# WKUP_CTRL_MMR0_CFG0 register map
Vendor: Texas Instruments
Registers are 32-bit, read-write, reset 0x0 unless marked. A register's access mark holds for its fields unless they carry their own. Offsets are as the file gives them; [hi:lo] are bit positions; {n}, {i} and the like mark numbered series.

## WKUP_CTRL_MMR0_CFG0 (part 7 of 11)
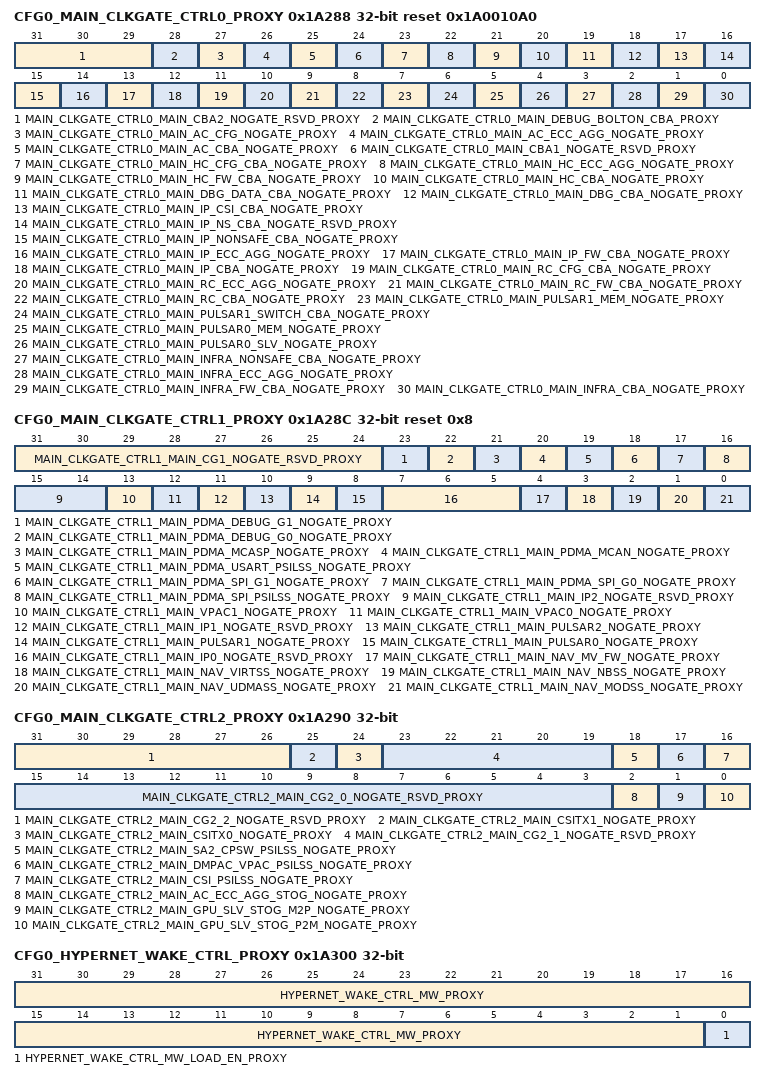
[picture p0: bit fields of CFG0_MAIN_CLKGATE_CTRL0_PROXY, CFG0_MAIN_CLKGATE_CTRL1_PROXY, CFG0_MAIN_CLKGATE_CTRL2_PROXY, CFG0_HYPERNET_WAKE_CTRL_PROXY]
0x1A288 CFG0_MAIN_CLKGATE_CTRL0_PROXY reset 0x1A0010A0 — Controls the power clock gating feature of MAIN domain modules and busses
  [31:29] MAIN_CLKGATE_CTRL0_MAIN_CBA2_NOGATE_RSVD_PROXY — MAIN CBA reserved clock gate disable. These bits should remain unchanged (written only with their default value) to maintain compatibility with future devices. 0 - Clocks are gated on idle for power savings 1 - Clocks are not gated on idle, power saving disabled
  [28] MAIN_CLKGATE_CTRL0_MAIN_DEBUG_BOLTON_CBA_PROXY — MAIN domain debug bolton bus (debug_bolton_cbass) clock gate disable. 0 - Clocks are gated on idle for power savings 1 - Clocks are not gated on idle, power saving disabled
  [27] MAIN_CLKGATE_CTRL0_MAIN_AC_CFG_NOGATE_PROXY — MAIN domain AC Configuration bus (ac_cfg_fw_cbass) clock gate disable. 0 - Clocks are gated on idle for power savings 1 - Clocks are not gated on idle, power saving disabled
  [26] MAIN_CLKGATE_CTRL0_MAIN_AC_ECC_AGG_NOGATE_PROXY — MAIN domain AC ECC aggregator bus (ac_pipe_ecc_aggr) clock gate disable. 0 - Clocks are gated on idle for power savings 1 - Clocks are not gated on idle, power saving disabled
  [25] MAIN_CLKGATE_CTRL0_MAIN_AC_CBA_NOGATE_PROXY — MAIN domain AC Firewall bus (ac_pipe_cbass_main_fw_cbass_0) clock gate disable. 0 - Clocks are gated on idle for power savings 1 - Clocks are not gated on idle, power saving disabled
  [24] MAIN_CLKGATE_CTRL0_MAIN_CBA1_NOGATE_RSVD_PROXY — MAIN CBA reserved clock gate disable. These bits should remain unchanged (written only with their default value) to maintain compatibility with future devices. 0 - Clocks are gated on idle for power savings 1 - Clocks are not gated on idle, power saving disabled
  [23] MAIN_CLKGATE_CTRL0_MAIN_HC_CFG_CBA_NOGATE_PROXY — MAIN domain HC Configuration bus (hc_cfg_cbass_0) clock gate disable. 0 - Clocks are gated on idle for power savings 1 - Clocks are not gated on idle, power saving disabled
  [22] MAIN_CLKGATE_CTRL0_MAIN_HC_ECC_AGG_NOGATE_PROXY — MAIN domain HC ECC aggregator (nogate) clock gate disable. 0 - Clocks are gated on idle for power savings 1 - Clocks are not gated on idle, power saving disabled
  [21] MAIN_CLKGATE_CTRL0_MAIN_HC_FW_CBA_NOGATE_PROXY — MAIN domain HC Firewall bus (main_hc2_fw_cbass_0) clock gate disable. 0 - Clocks are gated on idle for power savings 1 - Clocks are not gated on idle, power saving disabled
  [20] MAIN_CLKGATE_CTRL0_MAIN_HC_CBA_NOGATE_PROXY — MAIN domain HC Data bus (hc2_cbass_0) clock gate disable. 0 - Clocks are gated on idle for power savings 1 - Clocks are not gated on idle, power saving disabled
  [19] MAIN_CLKGATE_CTRL0_MAIN_DBG_DATA_CBA_NOGATE_PROXY — MAIN domain Debug Data bus (debug_cbass) clock gate disable. 0 - Clocks are gated on idle for power savings 1 - Clocks are not gated on idle, power saving disabled
  [18] MAIN_CLKGATE_CTRL0_MAIN_DBG_CBA_NOGATE_PROXY — MAIN domain Debug bus (debug_cbass_wrap_main_0) clock gate disable. 0 - Clocks are gated on idle for power savings 1 - Clocks are not gated on idle, power saving disabled
  [17] MAIN_CLKGATE_CTRL0_MAIN_IP_CSI_CBA_NOGATE_PROXY — MAIN domain CSI bus (csi_cbass_0) clock gate disable. 0 - Clocks are gated on idle for power savings 1 - Clocks are not gated on idle, power saving disabled
  [16] MAIN_CLKGATE_CTRL0_MAIN_IP_NS_CBA_NOGATE_RSVD_PROXY — MAIN nonsafety CBA reserved clock gate disable. These bits should remain unchanged (written only with their default value) to maintain compatibility with future devices. 0 - Clocks are gated on idle for power savings 1 - Clocks are not gated on idle, power saving disabled
  [15] MAIN_CLKGATE_CTRL0_MAIN_IP_NONSAFE_CBA_NOGATE_PROXY — MAIN domain Interface Peripheral nonsafety IP bus (ipphy_cbass_0) clock gate disable. 0 - Clocks are gated on idle for power savings 1 - Clocks are not gated on idle, power saving disabled
  [14] MAIN_CLKGATE_CTRL0_MAIN_IP_ECC_AGG_NOGATE_PROXY — MAIN domain Interface Peripheral ECC aggregator (main_spi0_g0_main_0_ecc_aggr_main_0) clock gate disable. 0 - Clocks are gated on idle for power savings 1 - Clocks are not gated on idle, power saving disabled
  [13] MAIN_CLKGATE_CTRL0_MAIN_IP_FW_CBA_NOGATE_PROXY — MAIN domain Interface Peripheral Firewall bus (ipphy_cbass_main_fw_cbass) clock gate disable. 0 - Clocks are gated on idle for power savings 1 - Clocks are not gated on idle, power saving disabled
  [12] MAIN_CLKGATE_CTRL0_MAIN_IP_CBA_NOGATE_PROXY — MAIN domain Interface Peripheral bus (ipphy_safe_cbass_0) clock gate disable. 0 - Clocks are gated on idle for power savings 1 - Clocks are not gated on idle, power saving disabled
  [11] MAIN_CLKGATE_CTRL0_MAIN_RC_CFG_CBA_NOGATE_PROXY — MAIN domain RC Configuration bus (rc_cfg_cbass_0) clock gate disable. 0 - Clocks are gated on idle for power savings 1 - Clocks are not gated on idle, power saving disabled
  [10] MAIN_CLKGATE_CTRL0_MAIN_RC_ECC_AGG_NOGATE_PROXY — MAIN domain RC ECC aggregator (main_rc_ecc_aggr_main_0) clock gate disable. 0 - Clocks are gated on idle for power savings 1 - Clocks are not gated on idle, power saving disabled
  [9] MAIN_CLKGATE_CTRL0_MAIN_RC_FW_CBA_NOGATE_PROXY — MAIN domain RC Firewall bus (rc_cbass_main_fw_cbass) clock gate disable. 0 - Clocks are gated on idle for power savings 1 - Clocks are not gated on idle, power saving disabled
  [8] MAIN_CLKGATE_CTRL0_MAIN_RC_CBA_NOGATE_PROXY — MAIN domain RC Data bus (rc_cbass_0) clock gate disable. 0 - Clocks are gated on idle for power savings 1 - Clocks are not gated on idle, power saving disabled
  [7] MAIN_CLKGATE_CTRL0_MAIN_PULSAR1_MEM_NOGATE_PROXY — MAIN domain Pulsar 1 memory bus (pulsar1_mem_cbass) clock gate disable. 0 - Clocks are gated on idle for power savings 1 - Clocks are not gated on idle, power saving disabled
  [6] MAIN_CLKGATE_CTRL0_MAIN_PULSAR1_SWITCH_CBA_NOGATE_PROXY — MAIN domain Pulsar 1 peripheral switch bus (pulsar1_periph_switch_cbass) clock gate disable. 0 - Clocks are gated on idle for power savings 1 - Clocks are not gated on idle, power saving disabled
  [5] MAIN_CLKGATE_CTRL0_MAIN_PULSAR0_MEM_NOGATE_PROXY — MAIN domain Pulsar 0 memory bus (pulsar0_mem_cbass) clock gate disable. 0 - Clocks are gated on idle for power savings 1 - Clocks are not gated on idle, power saving disabled
  [4] MAIN_CLKGATE_CTRL0_MAIN_PULSAR0_SLV_NOGATE_PROXY — MAIN domain Pulsar slave bus (pulsar0_slv_cbass) clock gate disable. 0 - Clocks are gated on idle for power savings 1 - Clocks are not gated on idle, power saving disabled
  [3] MAIN_CLKGATE_CTRL0_MAIN_INFRA_NONSAFE_CBA_NOGATE_PROXY — MAIN domain Infrastructure non-safety IP bus (main_infra_non_safe_cbass) clock gate disable. 0 - Clocks are gated on idle for power savings 1 - Clocks are not gated on idle, power saving disabled
  [2] MAIN_CLKGATE_CTRL0_MAIN_INFRA_ECC_AGG_NOGATE_PROXY — MAIN domain Infrastructure ECC aggregator (main_infra_ecc_aggr) clock gate disable. 0 - Clocks are gated on idle for power savings 1 - Clocks are not gated on idle, power saving disabled
  [1] MAIN_CLKGATE_CTRL0_MAIN_INFRA_FW_CBA_NOGATE_PROXY — MAIN domain Infrastructure Firewall bus (main_infra_fw_cbass) clock gate disable. 0 - Clocks are gated on idle for power savings 1 - Clocks are not gated on idle, power saving disabled
  [0] MAIN_CLKGATE_CTRL0_MAIN_INFRA_CBA_NOGATE_PROXY — MAIN domain Infrastructure bus (main_infra_cbass) clock gate disable. 0 - Clocks are gated on idle for power savings 1 - Clocks are not gated on idle, power saving disabled
0x1A28C CFG0_MAIN_CLKGATE_CTRL1_PROXY reset 0x8 — Controls the power clock gating feature of MAIN domain modules and busses
  [31:24] MAIN_CLKGATE_CTRL1_MAIN_CG1_NOGATE_RSVD_PROXY — MAIN PDMA clock gate disable. These bits should remain unchanged (written only with their default value) to maintain compatibility with future devices. 0 - Clocks are gated on idle for power savings 1 - Clocks are not gated on idle, power saving disabled
  [23] MAIN_CLKGATE_CTRL1_MAIN_PDMA_DEBUG_G1_NOGATE_PROXY — MAIN domain PDMA Debug_G1 clock gate disable. 0 - Clocks are gated on idle for power savings 1 - Clocks are not gated on idle, power saving disabled
  [22] MAIN_CLKGATE_CTRL1_MAIN_PDMA_DEBUG_G0_NOGATE_PROXY — MAIN domain PDMA Debug_G0 clock gate disable. 0 - Clocks are gated on idle for power savings 1 - Clocks are not gated on idle, power saving disabled
  [21] MAIN_CLKGATE_CTRL1_MAIN_PDMA_MCASP_NOGATE_PROXY — MAIN domain PDMA MCASP clock gate disable. 0 - Clocks are gated on idle for power savings 1 - Clocks are not gated on idle, power saving disabled
  [20] MAIN_CLKGATE_CTRL1_MAIN_PDMA_MCAN_NOGATE_PROXY — MAIN domain PDMA MCAN clock gate disable. 0 - Clocks are gated on idle for power savings 1 - Clocks are not gated on idle, power saving disabled
  [19] MAIN_CLKGATE_CTRL1_MAIN_PDMA_USART_PSILSS_NOGATE_PROXY — MAIN domain PDMA USART PSILSS clock gate disable. 0 - Clocks are gated on idle for power savings 1 - Clocks are not gated on idle, power saving disabled
  [18] MAIN_CLKGATE_CTRL1_MAIN_PDMA_SPI_G1_NOGATE_PROXY — MAIN domain PDMA SPI_G1 clock gate disable. 0 - Clocks are gated on idle for power savings 1 - Clocks are not gated on idle, power saving disabled
  [17] MAIN_CLKGATE_CTRL1_MAIN_PDMA_SPI_G0_NOGATE_PROXY — MAIN domain PDMA SPI_G0 clock gate disable. 0 - Clocks are gated on idle for power savings 1 - Clocks are not gated on idle, power saving disabled
  [16] MAIN_CLKGATE_CTRL1_MAIN_PDMA_SPI_PSILSS_NOGATE_PROXY — MAIN domain PDMA SPI PSILSS clock gate disable. 0 - Clocks are gated on idle for power savings 1 - Clocks are not gated on idle, power saving disabled
  [15:14] MAIN_CLKGATE_CTRL1_MAIN_IP2_NOGATE_RSVD_PROXY — MAIN IP reserved clock gate disable. These bits should remain unchanged (written only with their default value) to maintain compatibility with future devices. 0 - Clocks are gated on idle for power savings 1 - Clocks are not gated on idle, power saving disabled
  [13] MAIN_CLKGATE_CTRL1_MAIN_VPAC1_NOGATE_PROXY — MAIN domain VPAC 1 clock gate disable. 0 - Clocks are gated on idle for power savings 1 - Clocks are not gated on idle, power saving disabled
  [12] MAIN_CLKGATE_CTRL1_MAIN_VPAC0_NOGATE_PROXY — MAIN domain VPAC 0 clock gate disable. 0 - Clocks are gated on idle for power savings 1 - Clocks are not gated on idle, power saving disabled
  [11] MAIN_CLKGATE_CTRL1_MAIN_IP1_NOGATE_RSVD_PROXY — MAIN IP reserved clock gate disable. These bits should remain unchanged (written only with their default value) to maintain compatibility with future devices. 0 - Clocks are gated on idle for power savings 1 - Clocks are not gated on idle, power saving disabled
  [10] MAIN_CLKGATE_CTRL1_MAIN_PULSAR2_NOGATE_PROXY — MAIN domain Pulsar 2 clock gate disable. 0 - Clocks are gated on idle for power savings 1 - Clocks are not gated on idle, power saving disabled
  [9] MAIN_CLKGATE_CTRL1_MAIN_PULSAR1_NOGATE_PROXY — MAIN domain Pulsar 1 clock gate disable. 0 - Clocks are gated on idle for power savings 1 - Clocks are not gated on idle, power saving disabled
  [8] MAIN_CLKGATE_CTRL1_MAIN_PULSAR0_NOGATE_PROXY — MAIN domain Pulsar 0 clock gate disable. 0 - Clocks are gated on idle for power savings 1 - Clocks are not gated on idle, power saving disabled
  [7:5] MAIN_CLKGATE_CTRL1_MAIN_IP0_NOGATE_RSVD_PROXY — MAIN IP reserved clock gate disable. These bits should remain unchanged (written only with their default value) to maintain compatibility with future devices. 0 - Clocks are gated on idle for power savings 1 - Clocks are not gated on idle, power saving disabled
  [4] MAIN_CLKGATE_CTRL1_MAIN_NAV_MV_FW_NOGATE_PROXY — MAIN NavSS Mod/Virt Firewall interface clock gate disable. 0 - Clocks are gated on idle for power savings 1 - Clocks are not gated on idle, power saving disabled
  [3] MAIN_CLKGATE_CTRL1_MAIN_NAV_VIRTSS_NOGATE_PROXY — MAIN NavSS VIRTSS interface clock gate disable. 0 - Clocks are gated on idle for power savings 1 - Clocks are not gated on idle, power saving disabled
  [2] MAIN_CLKGATE_CTRL1_MAIN_NAV_NBSS_NOGATE_PROXY — MAIN NavSS NB interface clock gate disable. 0 - Clocks are gated on idle for power savings 1 - Clocks are not gated on idle, power saving disabled
  [1] MAIN_CLKGATE_CTRL1_MAIN_NAV_UDMASS_NOGATE_PROXY — Main NavSS UDMA interface clock gate disable. 0 - Clocks are gated on idle for power savings 1 - Clocks are not gated on idle, power saving disabled
  [0] MAIN_CLKGATE_CTRL1_MAIN_NAV_MODSS_NOGATE_PROXY — MAIN NavSS MODSS interface clock gate disable. 0 - Clocks are gated on idle for power savings 1 - Clocks are not gated on idle, power saving disabled
0x1A290 CFG0_MAIN_CLKGATE_CTRL2_PROXY — Controls the power clock gating feature of MAIN domain modules and busses
  [31:26] MAIN_CLKGATE_CTRL2_MAIN_CG2_2_NOGATE_RSVD_PROXY — MAIN domain spare clock gate disable. These bits should remain unchanged (written only with their default value) to maintain compatibility with future devices. 0 - Clocks are gated on idle for power savings 1 - Clocks are not gated on idle, power saving disabled
  [25] MAIN_CLKGATE_CTRL2_MAIN_CSITX1_NOGATE_PROXY — MAIN domain CSI_TX1 clock gate disable. 0 - Clocks are gated on idle for power savings 1 - Clocks are not gated on idle, power saving disabled
  [24] MAIN_CLKGATE_CTRL2_MAIN_CSITX0_NOGATE_PROXY — MAIN domain CSI_TX0 clock gate disable. 0 - Clocks are gated on idle for power savings 1 - Clocks are not gated on idle, power saving disabled
  [23:19] MAIN_CLKGATE_CTRL2_MAIN_CG2_1_NOGATE_RSVD_PROXY — MAIN domain spare clock gate disable. These bits should remain unchanged (written only with their default value) to maintain compatibility with future devices. 0 - Clocks are gated on idle for power savings 1 - Clocks are not gated on idle, power saving disabled
  [18] MAIN_CLKGATE_CTRL2_MAIN_SA2_CPSW_PSILSS_NOGATE_PROXY — MAIN domain SA2_UL/SPCW PSILSS clock gate disable. 0 - Clocks are gated on idle for power savings 1 - Clocks are not gated on idle, power saving disabled
  [17] MAIN_CLKGATE_CTRL2_MAIN_DMPAC_VPAC_PSILSS_NOGATE_PROXY — MAIN domain DMPAC/VPAC PSILSS clock gate disable. 0 - Clocks are gated on idle for power savings 1 - Clocks are not gated on idle, power saving disabled
  [16] MAIN_CLKGATE_CTRL2_MAIN_CSI_PSILSS_NOGATE_PROXY — MAIN domain CSI PSILSS clock gate disable. 0 - Clocks are gated on idle for power savings 1 - Clocks are not gated on idle, power saving disabled
  [15:3] MAIN_CLKGATE_CTRL2_MAIN_CG2_0_NOGATE_RSVD_PROXY — MAIN domain spare clock gate disable. These bits should remain unchanged (written only with their default value) to maintain compatibility with future devices. 0 - Clocks are gated on idle for power savings 1 - Clocks are not gated on idle, power saving disabled
  [2] MAIN_CLKGATE_CTRL2_MAIN_AC_ECC_AGG_STOG_NOGATE_PROXY — MAIN domain ac ECC aggregator Slave Timeout Gasket (main_ac_ecc_aggr_stog) clock gate disable. 0 - Clocks are gated on idle for power savings 1 - Clocks are not gated on idle, power saving disabled
  [1] MAIN_CLKGATE_CTRL2_MAIN_GPU_SLV_STOG_M2P_NOGATE_PROXY — MAIN domain GPU Slave Timeout Gasket output (main_gpu_slv_stog_m2p_pwr_dis) clock gate disable. 0 - Clocks are gated on idle for power savings 1 - Clocks are not gated on idle, power saving disabled
  [0] MAIN_CLKGATE_CTRL2_MAIN_GPU_SLV_STOG_P2M_NOGATE_PROXY — MAIN domain GPU Slave Timeout Gasket input (main_gpu_slv_stog_p2m_pwr_dis) clock gate disable. 0 - Clocks are gated on idle for power savings 1 - Clocks are not gated on idle, power saving disabled
0x1A294 CFG0_MAIN_CLKGATE_CTRL3_PROXY — Controls the power clock gating feature of MAIN domain modules and busses
  [31:0] MAIN_CLKGATE_CTRL3_MAIN_CG3_NOGATE_RSVD_PROXY — MAIN domain spare clock gate disable. These bits should remain unchanged (written only with their default value) to maintain compatibility with future devices. 0 - Clocks are gated on idle for power savings 1 - Clocks are not gated on idle, power saving disabled
0x1A300 CFG0_HYPERNET_WAKE_CTRL_PROXY — Controls the operation of IO wakeup on the MAIN HYPERNET pins
  [31:1] HYPERNET_WAKE_CTRL_MW_PROXY — HYPERNET IO magic word. This 31-bit value that enables placing of the HYPERNET I/Os into isolation for daisy-chain wakeup operation. 0x2AAAAAAA - Magic word value to enable isolation when qualified with mw_load bit Others - Any other value will prevent isolation when mw_load transitions from 0 to 1.
  [0] HYPERNET_WAKE_CTRL_MW_LOAD_EN_PROXY — Magic word load enableSetting this bit to 1 loads and locks the mw field for HYPERNET IO isolation. If the mw field matches the magic word value then the value is latched into the HYPERNET IO voltage domain and HYPERNET IO isolation is enabled. 0 - Unlock and do not load mw value for comparison 1 - Load and lock mw for magic word value comparison
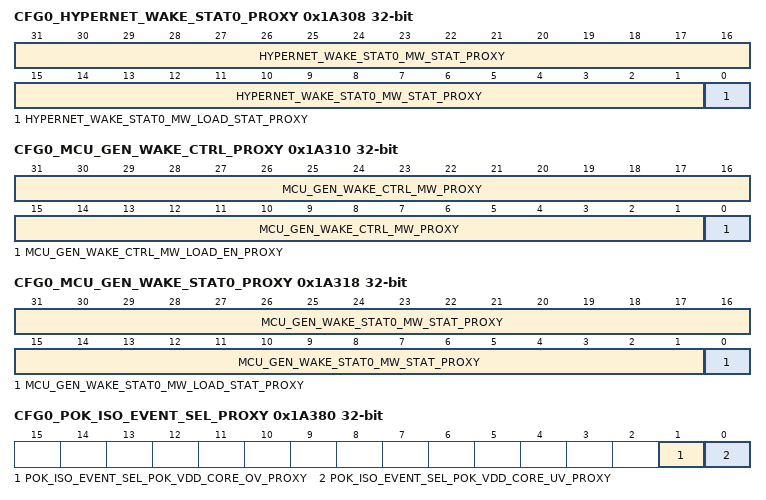
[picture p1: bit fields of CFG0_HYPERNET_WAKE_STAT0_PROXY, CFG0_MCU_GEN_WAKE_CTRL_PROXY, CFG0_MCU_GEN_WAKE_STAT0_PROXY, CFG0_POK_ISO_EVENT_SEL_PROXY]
0x1A308 CFG0_HYPERNET_WAKE_STAT0_PROXY ro — Provides the status of MAIN HYPERNET_WAKE control bits
  [31:1] HYPERNET_WAKE_STAT0_MW_STAT_PROXY — HYPERNET magic word statusIndicates the latched value of the mw field.
  [0] HYPERNET_WAKE_STAT0_MW_LOAD_STAT_PROXY — Magic word load status.Indicates the latched value of the mw_load_en bit
0x1A30C CFG0_HYPERNET_WAKE_STAT1_PROXY ro — Provides MAIN HYPERNET IO isolation status
  [0] HYPERNET_WAKE_STAT1_HYPERNET_IO_MODE_PROXY — Indicates if HYPERNET IO wakeup mode is enabled. 0 - Not enabled (load_en not set or mw doesn't match magic word) 1 - HYPERNET IO mode enabled
0x1A310 CFG0_MCU_GEN_WAKE_CTRL_PROXY — Controls the operation of IO wakeup on the MCU_GENERAL pins
  [31:1] MCU_GEN_WAKE_CTRL_MW_PROXY — MCU_GENERAL IO magic word. This 31-bit value that enables placing of the MCU_GENERAL I/Os into isolation for daisy-chain wakeup operation. 0x2AAAAAAA - Magic word value to enable isolation when qualified with mw_load bit Others - Any other value will prevent isolation when mw_load transitions from 0 to 1.
  [0] MCU_GEN_WAKE_CTRL_MW_LOAD_EN_PROXY — Magic word load enableSetting this bit to 1 loads and locks the mw field for MCU_GENERAL IO isolation. If the mw field matches the magic word value then the value is latched into the MCU_GENERAL IO voltage domain and MCU_GENERAL IO isolation is enabled. 0 - Unlock and do not load mw value for comparison 1 - Load and lock mw for magic word value comparison
0x1A318 CFG0_MCU_GEN_WAKE_STAT0_PROXY ro — Provides the status of MCU_GEN_WAKE control bits
  [31:1] MCU_GEN_WAKE_STAT0_MW_STAT_PROXY — MCU_GENERAL magic word statusIndicates the latched value of the mw field.
  [0] MCU_GEN_WAKE_STAT0_MW_LOAD_STAT_PROXY — Magic word load status.Indicates the latched value of the mw_load_en bit
0x1A31C CFG0_MCU_GEN_WAKE_STAT1_PROXY ro — Provides MCU_GENERAL IO isolation status
  [0] MCU_GEN_WAKE_STAT1_MCU_GEN_IO_MODE_PROXY — Indicates if MCU_GENERAL IO wakeup mode is enabled. 0 - Not enabled (load_en not set or mw doesn't match magic word) 1 - MCU_GENERAL IO mode enabled
0x1A380 CFG0_POK_ISO_EVENT_SEL_PROXY — Determines which POK events activate isolation features
  [1] POK_ISO_EVENT_SEL_POK_VDD_CORE_OV_PROXY — VDD_CORE overvoltage detection triggers enabled isolation actions
  [0] POK_ISO_EVENT_SEL_POK_VDD_CORE_UV_PROXY — VDD_CORE undervoltage detection triggers enabled isolation actions
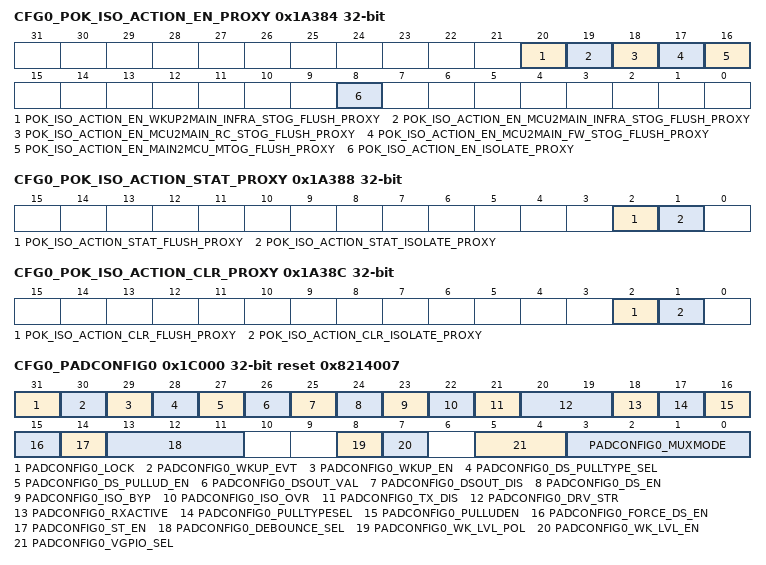
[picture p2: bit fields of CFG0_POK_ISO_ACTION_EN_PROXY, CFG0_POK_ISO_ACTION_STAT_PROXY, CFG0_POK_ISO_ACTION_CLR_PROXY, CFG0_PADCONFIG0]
0x1A384 CFG0_POK_ISO_ACTION_EN_PROXY — Selects which isolation actions to perform when POK events as selected in POK_ISO_EVENT_SEL occur
  [20] POK_ISO_ACTION_EN_WKUP2MAIN_INFRA_STOG_FLUSH_PROXY — WKUP to Main INFRA slave timeout gasket flush enable: 0 - Enabled POK events have no effect on this gasket 1 - Enabled POK events will assert the flush for this gasket
  [19] POK_ISO_ACTION_EN_MCU2MAIN_INFRA_STOG_FLUSH_PROXY — MCU to Main INFRA slave timeout gasket flush enable: 0 - Enabled POK events have no effect on this gasket 1 - Enabled POK events will assert the flush for this gasket
  [18] POK_ISO_ACTION_EN_MCU2MAIN_RC_STOG_FLUSH_PROXY — MCU to Main RC slave timeout gasket flush enable: 0 - Enabled POK events have no effect on this gasket 1 - Enabled POK events will assert the flush for this gasket
  [17] POK_ISO_ACTION_EN_MCU2MAIN_FW_STOG_FLUSH_PROXY — MCU to Main FW slave timeout gasket flush enable: 0 - Enabled POK events have no effect on this gasket 1 - Enabled POK events will assert the flush for this gasket
  [16] POK_ISO_ACTION_EN_MAIN2MCU_MTOG_FLUSH_PROXY — MAIN to MCU master timeout gasket flush enable: 0 - Enabled POK events have no effect on this gasket 1 - Enabled POK events will assert the flush for this gasket
  [8] POK_ISO_ACTION_EN_ISOLATE_PROXY — If enabled, the isolate signal will be asserted after all enabled flush signals have been asserted for 4 of their respective time-out gasket clocks when any selected POK event occurs. 0 - Isolation is not asserted on selected POK event 1 - Isolation signal is asserted on selected POK event after enabled TOG flush
0x1A388 CFG0_POK_ISO_ACTION_STAT_PROXY ro — Indicates the status of enabled POK isolation actions
  [2] POK_ISO_ACTION_STAT_FLUSH_PROXY — POK activated timeout gasket flush statusThis signal will remain asserted until a 1 is written to the POK_ISO_ACTION_CLR_flush bit. 0 - No gasket flush is being asserted by enabled POK event 1 - Enabled gasket flush signals are being asserted due to an enabled POK event
  [1] POK_ISO_ACTION_STAT_ISOLATE_PROXY — POK activated Isolate statusThis signal will remain asserted until a 1 is written to the POK_ISO_ACTION_CLR_isolate bit. 0 - No isolate is being asserted by enabled POK event 1 - Isolate signal is being asserted due to an enabled POK event
0x1A38C CFG0_POK_ISO_ACTION_CLR_PROXY — Selects which active POK isolation actions to clear
  [2] POK_ISO_ACTION_CLR_FLUSH_PROXY — POK activated timeout gasket flush clearAlways read as 0. Writing 1 deasserts POK activated timeot gasket flush signals. 0 - Writing 0 has no effect. Bit always reads as 0 1 - Deassert gasket flush signals. Bit will clear to 0 after write.
  [1] POK_ISO_ACTION_CLR_ISOLATE_PROXY — POK activated isolate clearAlways read as 0. Writing 1 deasserts POK activated isolate signal. 0 - Writing 0 has no effect. Bit always reads as 0 1 - Deassert isolate signal. Bit will clear to 0 after write.
{0x1B100+4i} CFG0_CLAIMREG_P6_R{i} (i=0..7)
  [31:0] CLAIMREG_P6_R{i} — Claim bits for Partition 6
0x1C000 CFG0_PADCONFIG0 access per field reset 0x8214007 — Register to control pin configuration and muxing
  [31] PADCONFIG0_LOCK rw — Lock 0 - Padconfig register is unlocked 1 - Padconfig register is locked from further writes
  [30] PADCONFIG0_WKUP_EVT ro — Wakeup event status 0 - No wake event on pin 1 - Wake event occurred on pin
  [29] PADCONFIG0_WKUP_EN rw — Wakeup enable 0 - Wakeup operation disabled 1 - Wakeup operation enabled
  [28] PADCONFIG0_DS_PULLTYPE_SEL rw — Deep Sleep pull-up/down selection 0 - Offmode pulldown selected 1 - Offmode pullup selected
  [27] PADCONFIG0_DS_PULLUD_EN rw — Deep Sleep pull-up/down enable (active low) 0 - Pullup / pulldown is enabled 1 - Pullup / pulldown is disabled
  [26] PADCONFIG0_DSOUT_VAL rw — Deep Sleep output value 0 - Output value is 0 1 - Output value is 1
  [25] PADCONFIG0_DSOUT_DIS rw — Deep Sleep output enable 0 - Output enabled 1 - Output disabled
  [24] PADCONFIG0_DS_EN rw — Deep Sleep override control 0 - IO keeps its previous state when Deep Sleep is active 1 - IO state is forced to OFF mode value when Deep Sleep is active
  [23] PADCONFIG0_ISO_BYP rw — Isolation Bypass0 - IO isolation is preserved1 - IO isolation is bypassed
  [22] PADCONFIG0_ISO_OVR rw — Isolation Override0 - IO isolation is preserved1 - IO isolation is overridden
  [21] PADCONFIG0_TX_DIS rw — Driver Disable0 - Driver is enabled1 - Driver is disabled
  [20:19] PADCONFIG0_DRV_STR rw — Drive Strength Control . Selects the drive strength value for LVCMOS pins. (Does not apply to other pin types)
  [18] PADCONFIG0_RXACTIVE rw — Input enable for the Pad0 - Receiver disabled1 - Receiver enabled
  [17] PADCONFIG0_PULLTYPESEL rw — Pad Pullup / Pulldown type selection0 - Pulldown selected1 - Pullup selected
  [16] PADCONFIG0_PULLUDEN rw — Pad Pullup / Pulldown enable. This is an active low signal.0 - Pullup / Pulldown enabled1 - Pullup / Pulldown disabled
  [15] PADCONFIG0_FORCE_DS_EN rw — Enable pad Deep Sleep controls by overriding SMS gating0 - Deep Sleep pad controls are gated by the SMS1 - Activate Deep Sleep pad controls (override SMS gating logic)
  [14] PADCONFIG0_ST_EN rw — Receiver Schmitt Trigger enable 0 - Schmitt trigger input disabled 1 - Schmitt trigger input enabled
  [13:11] PADCONFIG0_DEBOUNCE_SEL rw — Selects the debounce period for the pad.
  [8] PADCONFIG0_WK_LVL_POL rw — Level Sensitive Wakeup PolarityThis bit is not relevant unless wk_lvl_en is set to 1'b1.0 - Low. A low (0) value on the pin causes a wakeup1 - High. A high (1) value on the pin causes a wakeup
  [7] PADCONFIG0_WK_LVL_EN rw — Level Sensitive Wakeup Enable0 - Disabled. Wakeup is triggered by change of the pin input value1 - Enabled. Wakeup is triggered when the pin matches the value specified by wk_lvl_pol. The chosen polarity must be maintained. (e.g. until wakeup completion is confirmed)
  [5:4] PADCONFIG0_VGPIO_SEL rw — Virtual WKUP_GPIO instance select.These bits select which instance of GPIO is used for this I/O pad. This allows protection between two different Processor virtual worlds. These bits have no effect if GPIO mode (muxmode=7) is not selected for the PAD. Field values (Others are reserved): 2'b00 - Implement GPIO in GPIO_WKUP_0 instance 2'b01 - Implement GPIO in GPIO_WKUP_1 instance
  [3:0] PADCONFIG0_MUXMODE rw — Pad functional signal mux selection Field values (Others are reserved): 0000b - Mux Mode 0 0001b - Mux Mode 1 0010b - Mux Mode 2 0011b - Mux Mode 3 0100b - Mux Mode 4 0101b - Mux Mode 5 0110b - Mux Mode 6 0111b - Mux Mode 7 1111b - Mux Mode 15
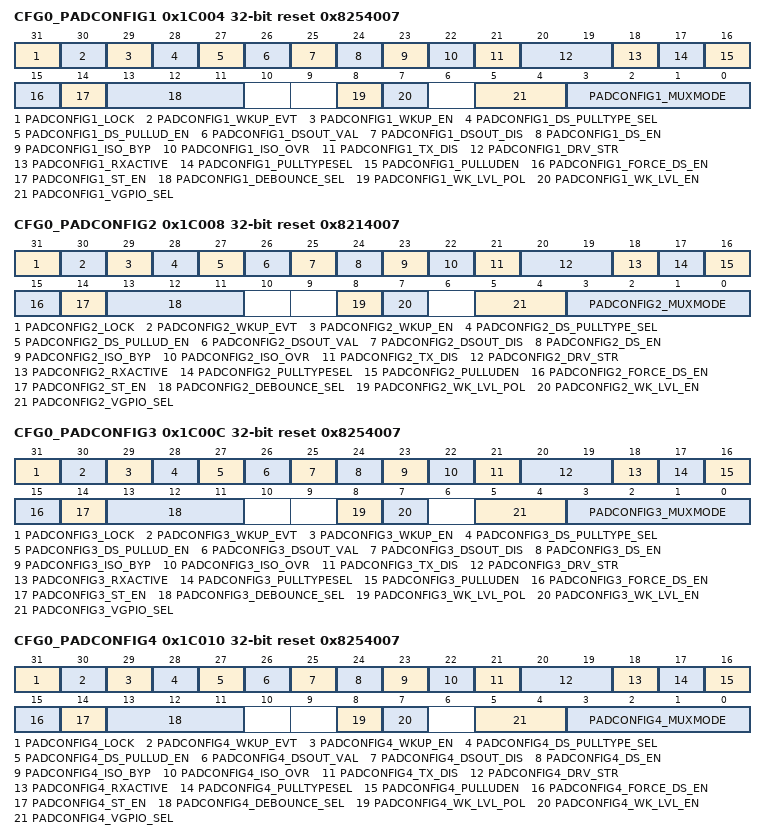
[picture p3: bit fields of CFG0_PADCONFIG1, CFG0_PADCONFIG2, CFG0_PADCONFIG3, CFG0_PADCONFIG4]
0x1C004 CFG0_PADCONFIG1 access per field reset 0x8254007 — Register to control pin configuration and muxing
  [31] PADCONFIG1_LOCK rw — Lock 0 - Padconfig register is unlocked 1 - Padconfig register is locked from further writes
  [30] PADCONFIG1_WKUP_EVT ro — Wakeup event status 0 - No wake event on pin 1 - Wake event occurred on pin
  [29] PADCONFIG1_WKUP_EN rw — Wakeup enable 0 - Wakeup operation disabled 1 - Wakeup operation enabled
  [28] PADCONFIG1_DS_PULLTYPE_SEL rw — Deep Sleep pull-up/down selection 0 - Offmode pulldown selected 1 - Offmode pullup selected
  [27] PADCONFIG1_DS_PULLUD_EN rw — Deep Sleep pull-up/down enable (active low) 0 - Pullup / pulldown is enabled 1 - Pullup / pulldown is disabled
  [26] PADCONFIG1_DSOUT_VAL rw — Deep Sleep output value 0 - Output value is 0 1 - Output value is 1
  [25] PADCONFIG1_DSOUT_DIS rw — Deep Sleep output enable 0 - Output enabled 1 - Output disabled
  [24] PADCONFIG1_DS_EN rw — Deep Sleep override control 0 - IO keeps its previous state when Deep Sleep is active 1 - IO state is forced to OFF mode value when Deep Sleep is active
  [23] PADCONFIG1_ISO_BYP rw — Isolation Bypass0 - IO isolation is preserved1 - IO isolation is bypassed
  [22] PADCONFIG1_ISO_OVR rw — Isolation Override0 - IO isolation is preserved1 - IO isolation is overridden
  [21] PADCONFIG1_TX_DIS rw — Driver Disable0 - Driver is enabled1 - Driver is disabled
  [20:19] PADCONFIG1_DRV_STR rw — Drive Strength Control . Selects the drive strength value for LVCMOS pins. (Does not apply to other pin types)
  [18] PADCONFIG1_RXACTIVE rw — Input enable for the Pad0 - Receiver disabled1 - Receiver enabled
  [17] PADCONFIG1_PULLTYPESEL rw — Pad Pullup / Pulldown type selection0 - Pulldown selected1 - Pullup selected
  [16] PADCONFIG1_PULLUDEN rw — Pad Pullup / Pulldown enable. This is an active low signal.0 - Pullup / Pulldown enabled1 - Pullup / Pulldown disabled
  [15] PADCONFIG1_FORCE_DS_EN rw — Enable pad Deep Sleep controls by overriding SMS gating0 - Deep Sleep pad controls are gated by the SMS1 - Activate Deep Sleep pad controls (override SMS gating logic)
  [14] PADCONFIG1_ST_EN rw — Receiver Schmitt Trigger enable 0 - Schmitt trigger input disabled 1 - Schmitt trigger input enabled
  [13:11] PADCONFIG1_DEBOUNCE_SEL rw — Selects the debounce period for the pad.
  [8] PADCONFIG1_WK_LVL_POL rw — Level Sensitive Wakeup PolarityThis bit is not relevant unless wk_lvl_en is set to 1'b1.0 - Low. A low (0) value on the pin causes a wakeup1 - High. A high (1) value on the pin causes a wakeup
  [7] PADCONFIG1_WK_LVL_EN rw — Level Sensitive Wakeup Enable0 - Disabled. Wakeup is triggered by change of the pin input value1 - Enabled. Wakeup is triggered when the pin matches the value specified by wk_lvl_pol. The chosen polarity must be maintained. (e.g. until wakeup completion is confirmed)
  [5:4] PADCONFIG1_VGPIO_SEL rw — Virtual WKUP_GPIO instance select.These bits select which instance of GPIO is used for this I/O pad. This allows protection between two different Processor virtual worlds. These bits have no effect if GPIO mode (muxmode=7) is not selected for the PAD. Field values (Others are reserved): 2'b00 - Implement GPIO in GPIO_WKUP_0 instance 2'b01 - Implement GPIO in GPIO_WKUP_1 instance
  [3:0] PADCONFIG1_MUXMODE rw — Pad functional signal mux selection Field values (Others are reserved): 0000b - Mux Mode 0 0001b - Mux Mode 1 0010b - Mux Mode 2 0011b - Mux Mode 3 0100b - Mux Mode 4 0101b - Mux Mode 5 0110b - Mux Mode 6 0111b - Mux Mode 7 1111b - Mux Mode 15
0x1C008 CFG0_PADCONFIG2 access per field reset 0x8214007 — Register to control pin configuration and muxing
  [31] PADCONFIG2_LOCK rw — Lock 0 - Padconfig register is unlocked 1 - Padconfig register is locked from further writes
  [30] PADCONFIG2_WKUP_EVT ro — Wakeup event status 0 - No wake event on pin 1 - Wake event occurred on pin
  [29] PADCONFIG2_WKUP_EN rw — Wakeup enable 0 - Wakeup operation disabled 1 - Wakeup operation enabled
  [28] PADCONFIG2_DS_PULLTYPE_SEL rw — Deep Sleep pull-up/down selection 0 - Offmode pulldown selected 1 - Offmode pullup selected
  [27] PADCONFIG2_DS_PULLUD_EN rw — Deep Sleep pull-up/down enable (active low) 0 - Pullup / pulldown is enabled 1 - Pullup / pulldown is disabled
  [26] PADCONFIG2_DSOUT_VAL rw — Deep Sleep output value 0 - Output value is 0 1 - Output value is 1
  [25] PADCONFIG2_DSOUT_DIS rw — Deep Sleep output enable 0 - Output enabled 1 - Output disabled
  [24] PADCONFIG2_DS_EN rw — Deep Sleep override control 0 - IO keeps its previous state when Deep Sleep is active 1 - IO state is forced to OFF mode value when Deep Sleep is active
  [23] PADCONFIG2_ISO_BYP rw — Isolation Bypass0 - IO isolation is preserved1 - IO isolation is bypassed
  [22] PADCONFIG2_ISO_OVR rw — Isolation Override0 - IO isolation is preserved1 - IO isolation is overridden
  [21] PADCONFIG2_TX_DIS rw — Driver Disable0 - Driver is enabled1 - Driver is disabled
  [20:19] PADCONFIG2_DRV_STR rw — Drive Strength Control . Selects the drive strength value for LVCMOS pins. (Does not apply to other pin types)
  [18] PADCONFIG2_RXACTIVE rw — Input enable for the Pad0 - Receiver disabled1 - Receiver enabled
  [17] PADCONFIG2_PULLTYPESEL rw — Pad Pullup / Pulldown type selection0 - Pulldown selected1 - Pullup selected
  [16] PADCONFIG2_PULLUDEN rw — Pad Pullup / Pulldown enable. This is an active low signal.0 - Pullup / Pulldown enabled1 - Pullup / Pulldown disabled
  [15] PADCONFIG2_FORCE_DS_EN rw — Enable pad Deep Sleep controls by overriding SMS gating0 - Deep Sleep pad controls are gated by the SMS1 - Activate Deep Sleep pad controls (override SMS gating logic)
  [14] PADCONFIG2_ST_EN rw — Receiver Schmitt Trigger enable 0 - Schmitt trigger input disabled 1 - Schmitt trigger input enabled
  [13:11] PADCONFIG2_DEBOUNCE_SEL rw — Selects the debounce period for the pad.
  [8] PADCONFIG2_WK_LVL_POL rw — Level Sensitive Wakeup PolarityThis bit is not relevant unless wk_lvl_en is set to 1'b1.0 - Low. A low (0) value on the pin causes a wakeup1 - High. A high (1) value on the pin causes a wakeup
  [7] PADCONFIG2_WK_LVL_EN rw — Level Sensitive Wakeup Enable0 - Disabled. Wakeup is triggered by change of the pin input value1 - Enabled. Wakeup is triggered when the pin matches the value specified by wk_lvl_pol. The chosen polarity must be maintained. (e.g. until wakeup completion is confirmed)
  [5:4] PADCONFIG2_VGPIO_SEL rw — Virtual WKUP_GPIO instance select.These bits select which instance of GPIO is used for this I/O pad. This allows protection between two different Processor virtual worlds. These bits have no effect if GPIO mode (muxmode=7) is not selected for the PAD. Field values (Others are reserved): 2'b00 - Implement GPIO in GPIO_WKUP_0 instance 2'b01 - Implement GPIO in GPIO_WKUP_1 instance
  [3:0] PADCONFIG2_MUXMODE rw — Pad functional signal mux selection Field values (Others are reserved): 0000b - Mux Mode 0 0001b - Mux Mode 1 0010b - Mux Mode 2 0011b - Mux Mode 3 0100b - Mux Mode 4 0101b - Mux Mode 5 0110b - Mux Mode 6 0111b - Mux Mode 7 1111b - Mux Mode 15
0x1C00C CFG0_PADCONFIG3 access per field reset 0x8254007 — Register to control pin configuration and muxing
  [31] PADCONFIG3_LOCK rw — Lock 0 - Padconfig register is unlocked 1 - Padconfig register is locked from further writes
  [30] PADCONFIG3_WKUP_EVT ro — Wakeup event status 0 - No wake event on pin 1 - Wake event occurred on pin
  [29] PADCONFIG3_WKUP_EN rw — Wakeup enable 0 - Wakeup operation disabled 1 - Wakeup operation enabled
  [28] PADCONFIG3_DS_PULLTYPE_SEL rw — Deep Sleep pull-up/down selection 0 - Offmode pulldown selected 1 - Offmode pullup selected
  [27] PADCONFIG3_DS_PULLUD_EN rw — Deep Sleep pull-up/down enable (active low) 0 - Pullup / pulldown is enabled 1 - Pullup / pulldown is disabled
  [26] PADCONFIG3_DSOUT_VAL rw — Deep Sleep output value 0 - Output value is 0 1 - Output value is 1
  [25] PADCONFIG3_DSOUT_DIS rw — Deep Sleep output enable 0 - Output enabled 1 - Output disabled
  [24] PADCONFIG3_DS_EN rw — Deep Sleep override control 0 - IO keeps its previous state when Deep Sleep is active 1 - IO state is forced to OFF mode value when Deep Sleep is active
  [23] PADCONFIG3_ISO_BYP rw — Isolation Bypass0 - IO isolation is preserved1 - IO isolation is bypassed
  [22] PADCONFIG3_ISO_OVR rw — Isolation Override0 - IO isolation is preserved1 - IO isolation is overridden
  [21] PADCONFIG3_TX_DIS rw — Driver Disable0 - Driver is enabled1 - Driver is disabled
  [20:19] PADCONFIG3_DRV_STR rw — Drive Strength Control . Selects the drive strength value for LVCMOS pins. (Does not apply to other pin types)
  [18] PADCONFIG3_RXACTIVE rw — Input enable for the Pad0 - Receiver disabled1 - Receiver enabled
  [17] PADCONFIG3_PULLTYPESEL rw — Pad Pullup / Pulldown type selection0 - Pulldown selected1 - Pullup selected
  [16] PADCONFIG3_PULLUDEN rw — Pad Pullup / Pulldown enable. This is an active low signal.0 - Pullup / Pulldown enabled1 - Pullup / Pulldown disabled
  [15] PADCONFIG3_FORCE_DS_EN rw — Enable pad Deep Sleep controls by overriding SMS gating0 - Deep Sleep pad controls are gated by the SMS1 - Activate Deep Sleep pad controls (override SMS gating logic)
  [14] PADCONFIG3_ST_EN rw — Receiver Schmitt Trigger enable 0 - Schmitt trigger input disabled 1 - Schmitt trigger input enabled
  [13:11] PADCONFIG3_DEBOUNCE_SEL rw — Selects the debounce period for the pad.
  [8] PADCONFIG3_WK_LVL_POL rw — Level Sensitive Wakeup PolarityThis bit is not relevant unless wk_lvl_en is set to 1'b1.0 - Low. A low (0) value on the pin causes a wakeup1 - High. A high (1) value on the pin causes a wakeup
  [7] PADCONFIG3_WK_LVL_EN rw — Level Sensitive Wakeup Enable0 - Disabled. Wakeup is triggered by change of the pin input value1 - Enabled. Wakeup is triggered when the pin matches the value specified by wk_lvl_pol. The chosen polarity must be maintained. (e.g. until wakeup completion is confirmed)
  [5:4] PADCONFIG3_VGPIO_SEL rw — Virtual WKUP_GPIO instance select.These bits select which instance of GPIO is used for this I/O pad. This allows protection between two different Processor virtual worlds. These bits have no effect if GPIO mode (muxmode=7) is not selected for the PAD. Field values (Others are reserved): 2'b00 - Implement GPIO in GPIO_WKUP_0 instance 2'b01 - Implement GPIO in GPIO_WKUP_1 instance
  [3:0] PADCONFIG3_MUXMODE rw — Pad functional signal mux selection Field values (Others are reserved): 0000b - Mux Mode 0 0001b - Mux Mode 1 0010b - Mux Mode 2 0011b - Mux Mode 3 0100b - Mux Mode 4 0101b - Mux Mode 5 0110b - Mux Mode 6 0111b - Mux Mode 7 1111b - Mux Mode 15
0x1C010 CFG0_PADCONFIG4 access per field reset 0x8254007 — Register to control pin configuration and muxing
  [31] PADCONFIG4_LOCK rw — Lock 0 - Padconfig register is unlocked 1 - Padconfig register is locked from further writes
  [30] PADCONFIG4_WKUP_EVT ro — Wakeup event status 0 - No wake event on pin 1 - Wake event occurred on pin
  [29] PADCONFIG4_WKUP_EN rw — Wakeup enable 0 - Wakeup operation disabled 1 - Wakeup operation enabled
  [28] PADCONFIG4_DS_PULLTYPE_SEL rw — Deep Sleep pull-up/down selection 0 - Offmode pulldown selected 1 - Offmode pullup selected
  [27] PADCONFIG4_DS_PULLUD_EN rw — Deep Sleep pull-up/down enable (active low) 0 - Pullup / pulldown is enabled 1 - Pullup / pulldown is disabled
  [26] PADCONFIG4_DSOUT_VAL rw — Deep Sleep output value 0 - Output value is 0 1 - Output value is 1
  [25] PADCONFIG4_DSOUT_DIS rw — Deep Sleep output enable 0 - Output enabled 1 - Output disabled
  [24] PADCONFIG4_DS_EN rw — Deep Sleep override control 0 - IO keeps its previous state when Deep Sleep is active 1 - IO state is forced to OFF mode value when Deep Sleep is active
  [23] PADCONFIG4_ISO_BYP rw — Isolation Bypass0 - IO isolation is preserved1 - IO isolation is bypassed
  [22] PADCONFIG4_ISO_OVR rw — Isolation Override0 - IO isolation is preserved1 - IO isolation is overridden
  [21] PADCONFIG4_TX_DIS rw — Driver Disable0 - Driver is enabled1 - Driver is disabled
  [20:19] PADCONFIG4_DRV_STR rw — Drive Strength Control . Selects the drive strength value for LVCMOS pins. (Does not apply to other pin types)
  [18] PADCONFIG4_RXACTIVE rw — Input enable for the Pad0 - Receiver disabled1 - Receiver enabled
  [17] PADCONFIG4_PULLTYPESEL rw — Pad Pullup / Pulldown type selection0 - Pulldown selected1 - Pullup selected
  [16] PADCONFIG4_PULLUDEN rw — Pad Pullup / Pulldown enable. This is an active low signal.0 - Pullup / Pulldown enabled1 - Pullup / Pulldown disabled
  [15] PADCONFIG4_FORCE_DS_EN rw — Enable pad Deep Sleep controls by overriding SMS gating0 - Deep Sleep pad controls are gated by the SMS1 - Activate Deep Sleep pad controls (override SMS gating logic)
  [14] PADCONFIG4_ST_EN rw — Receiver Schmitt Trigger enable 0 - Schmitt trigger input disabled 1 - Schmitt trigger input enabled
  [13:11] PADCONFIG4_DEBOUNCE_SEL rw — Selects the debounce period for the pad.
  [8] PADCONFIG4_WK_LVL_POL rw — Level Sensitive Wakeup PolarityThis bit is not relevant unless wk_lvl_en is set to 1'b1.0 - Low. A low (0) value on the pin causes a wakeup1 - High. A high (1) value on the pin causes a wakeup
  [7] PADCONFIG4_WK_LVL_EN rw — Level Sensitive Wakeup Enable0 - Disabled. Wakeup is triggered by change of the pin input value1 - Enabled. Wakeup is triggered when the pin matches the value specified by wk_lvl_pol. The chosen polarity must be maintained. (e.g. until wakeup completion is confirmed)
  [5:4] PADCONFIG4_VGPIO_SEL rw — Virtual WKUP_GPIO instance select.These bits select which instance of GPIO is used for this I/O pad. This allows protection between two different Processor virtual worlds. These bits have no effect if GPIO mode (muxmode=7) is not selected for the PAD. Field values (Others are reserved): 2'b00 - Implement GPIO in GPIO_WKUP_0 instance 2'b01 - Implement GPIO in GPIO_WKUP_1 instance
  [3:0] PADCONFIG4_MUXMODE rw — Pad functional signal mux selection Field values (Others are reserved): 0000b - Mux Mode 0 0001b - Mux Mode 1 0010b - Mux Mode 2 0011b - Mux Mode 3 0100b - Mux Mode 4 0101b - Mux Mode 5 0110b - Mux Mode 6 0111b - Mux Mode 7 1111b - Mux Mode 15
